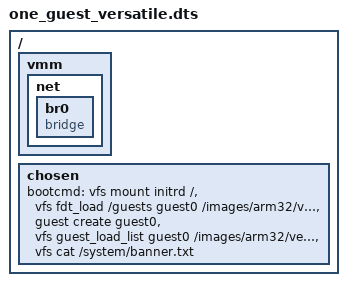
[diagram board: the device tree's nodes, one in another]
/*
 * Copyright (C) 2015 Jean-Christophe Dubois.
 * All rights reserved.
 *
 * This program is free software; you can redistribute it and/or modify
 * it under the terms of the GNU General Public License as published by
 * the Free Software Foundation; either version 2, or (at your option)
 * any later version.
 *
 * This program is distributed in the hope that it will be useful,
 * but WITHOUT ANY WARRANTY; without even the implied warranty of
 * MERCHANTABILITY or FITNESS FOR A PARTICULAR PURPOSE.  See the
 * GNU General Public License for more details.
 *
 * You should have received a copy of the GNU General Public License
 * along with this program; if not, write to the Free Software
 * Foundation, Inc., 675 Mass Ave, Cambridge, MA 02139, USA.
 *
 * @file one_guest_versatile.dts
 * @author Jean-Christophe Dubois (jcd@tribudubois.net)
 * @brief One guest versatile DTS file for i.MX25 PDK platform
 */

/dts-v1/;

#include "imx25-pdk.dtsi"

/ {
	vmm {
		net {
			br0 {
				device_type = "netswitch";
				compatible = "bridge";
			};
		};
	};

	chosen {
		bootcmd = /* Mount initrd device */
			  "vfs mount initrd /",

			  /* Load guest0 device tree from file */
			  "vfs fdt_load /guests guest0 /images/arm32/versatilepb.dtb mem0,physical_size,physsize,0x02000000 net0,switch,string,br0",

			  /* Create guest0 */
			  "guest create guest0",

			  /* Load guest0 images */
			  "vfs guest_load_list guest0 /images/arm32/versatilepb/nor_flash.list",

			  /* Print banner */
			  "vfs cat /system/banner.txt";
	};
};
